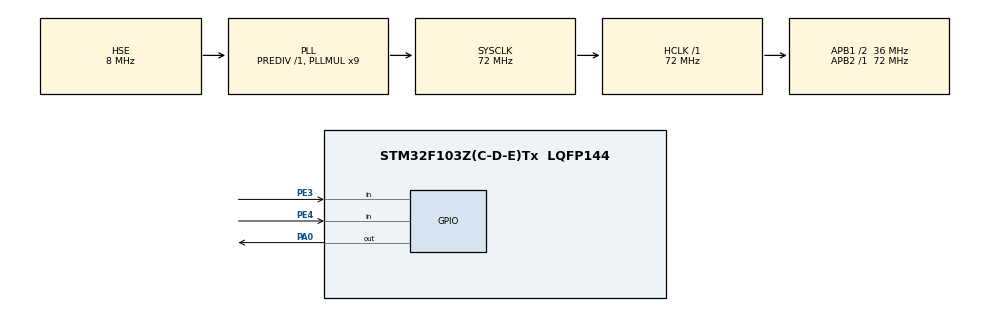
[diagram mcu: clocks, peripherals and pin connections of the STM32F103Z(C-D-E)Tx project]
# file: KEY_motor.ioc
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Mcu.Family=STM32F1
Mcu.Name=STM32F103Z(C-D-E)Tx
Mcu.Package=LQFP144
NVIC.PriorityGroup=NVIC_PRIORITYGROUP_4
OSC_IN.Mode=HSE-External-Oscillator
OSC_IN.Signal=RCC_OSC_IN
OSC_OUT.Mode=HSE-External-Oscillator
OSC_OUT.Signal=RCC_OSC_OUT
PA0-WKUP.GPIO_PuPd=GPIO_PULLUP
PA0-WKUP.GPIO_Speed=GPIO_SPEED_FREQ_HIGH
PA0-WKUP.PinState=GPIO_PIN_SET
PA0-WKUP.Signal=GPIO_Output
PA13.Mode=JTAG_5_pins
PA13.Signal=SYS_JTMS-SWDIO
PA14.Mode=JTAG_5_pins
PA14.Signal=SYS_JTCK-SWCLK
PA15.Mode=JTAG_5_pins
PA15.Signal=SYS_JTDI
PB3.Mode=JTAG_5_pins
PB3.Signal=SYS_JTDO-TRACESWO
PB4.Mode=JTAG_5_pins
PB4.Signal=SYS_NJTRST
PC14-OSC32_IN.Mode=LSE-External-Oscillator
PC14-OSC32_IN.Signal=RCC_OSC32_IN
PC15-OSC32_OUT.Mode=LSE-External-Oscillator
PC15-OSC32_OUT.Signal=RCC_OSC32_OUT
PE3.GPIO_PuPd=GPIO_PULLUP
PE3.Signal=GPIO_Input
PE4.GPIO_PuPd=GPIO_PULLUP
PE4.Signal=GPIO_Input
ProjectManager.HeapSize=0x200
ProjectManager.StackSize=0x400
ProjectManager.TargetToolchain=MDK-ARM V5.32
RCC.AHBFreq_Value=72000000
RCC.APB1CLKDivider=RCC_HCLK_DIV2
RCC.APB1Freq_Value=36000000
RCC.APB1TimFreq_Value=72000000
RCC.APB2Freq_Value=72000000
RCC.APB2TimFreq_Value=72000000
RCC.HCLKFreq_Value=72000000
RCC.PLLMUL=RCC_PLL_MUL9
RCC.PLLSourceVirtual=RCC_PLLSOURCE_HSE
RCC.SYSCLKFreq_VALUE=72000000
RCC.SYSCLKSource=RCC_SYSCLKSOURCE_PLLCLK
RCC.USBFreq_Value=72000000
board=custom

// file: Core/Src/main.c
/* USER CODE BEGIN Header */
/**
 ******************************************************************************
 * @file           : main.c
 * @brief          : Main program body
 ******************************************************************************
 * @attention
 *
 * Copyright (c) 2024 STMicroelectronics.
 * All rights reserved.
 *
 * This software is licensed under terms that can be found in the LICENSE file
 * in the root directory of this software component.
 * If no LICENSE file comes with this software, it is provided AS-IS.
 *
 ******************************************************************************
 */
/* USER CODE END Header */
#include "main.h"

void SystemClock_Config(void);
static void MX_GPIO_Init(void);

/* USER CODE BEGIN 0 */
void delay_us(uint32_t us)
{
  uint32_t count = us * (SystemCoreClock / 1000000) / 9;
  while (count--);
}

/* USER CODE END 0 */

int main(void)
{

  /* MCU Configuration--------------------------------------------------------*/

  /* Reset of all peripherals, Initializes the Flash interface and the Systick. */
  HAL_Init();

  /* Configure the system clock */
  SystemClock_Config();

  /* Initialize all configured peripherals */
  MX_GPIO_Init();
  /* USER CODE BEGIN 2 */
  uint16_t i = 0;
  /* USER CODE END 2 */

  /* Infinite loop */
  while (1)
  {

    /* USER CODE BEGIN 3 */

      for (i = 1500; i >= 500; i -= 10)
      {
        PA0(1);
        delay_us(i);
        PA0(0);
        delay_us(20000-i);
      }
      //for (i = 500; i <= 1500; i += 10)
      //{
      //  PA0(1);
      //  delay_us(i);
      //  PA0(0);
      //  delay_us(20000-i);
      //}
  }
  /* USER CODE END 3 */
}

void SystemClock_Config(void)
{
  RCC_OscInitTypeDef RCC_OscInitStruct = {0};
  RCC_ClkInitTypeDef RCC_ClkInitStruct = {0};

  /** Initializes the RCC Oscillators according to the specified parameters
   * in the RCC_OscInitTypeDef structure.
   */
  RCC_OscInitStruct.OscillatorType = RCC_OSCILLATORTYPE_HSE;
  RCC_OscInitStruct.HSEState = RCC_HSE_ON;
  RCC_OscInitStruct.HSEPredivValue = RCC_HSE_PREDIV_DIV1;
  RCC_OscInitStruct.HSIState = RCC_HSI_ON;
  RCC_OscInitStruct.PLL.PLLState = RCC_PLL_ON;
  RCC_OscInitStruct.PLL.PLLSource = RCC_PLLSOURCE_HSE;
  RCC_OscInitStruct.PLL.PLLMUL = RCC_PLL_MUL9;
  if (HAL_RCC_OscConfig(&RCC_OscInitStruct) != HAL_OK)
  {
    Error_Handler();
  }

  /** Initializes the CPU, AHB and APB buses clocks
   */
  RCC_ClkInitStruct.ClockType = RCC_CLOCKTYPE_HCLK | RCC_CLOCKTYPE_SYSCLK | RCC_CLOCKTYPE_PCLK1 | RCC_CLOCKTYPE_PCLK2;
  RCC_ClkInitStruct.SYSCLKSource = RCC_SYSCLKSOURCE_PLLCLK;
  RCC_ClkInitStruct.AHBCLKDivider = RCC_SYSCLK_DIV1;
  RCC_ClkInitStruct.APB1CLKDivider = RCC_HCLK_DIV2;
  RCC_ClkInitStruct.APB2CLKDivider = RCC_HCLK_DIV1;

  if (HAL_RCC_ClockConfig(&RCC_ClkInitStruct, FLASH_LATENCY_2) != HAL_OK)
  {
    Error_Handler();
  }
}

static void MX_GPIO_Init(void)
{
  GPIO_InitTypeDef GPIO_InitStruct = {0};

  /* GPIO Ports Clock Enable */
  __HAL_RCC_GPIOE_CLK_ENABLE();
  __HAL_RCC_GPIOC_CLK_ENABLE();
  __HAL_RCC_GPIOA_CLK_ENABLE();
  __HAL_RCC_GPIOB_CLK_ENABLE();

  /*Configure GPIO pin Output Level */
  HAL_GPIO_WritePin(GPIOA, GPIO_PIN_0, GPIO_PIN_SET);

  /*Configure GPIO pins : PE3 PE4 */
  GPIO_InitStruct.Pin = GPIO_PIN_3 | GPIO_PIN_4;
  GPIO_InitStruct.Mode = GPIO_MODE_INPUT;
  GPIO_InitStruct.Pull = GPIO_PULLUP;
  HAL_GPIO_Init(GPIOE, &GPIO_InitStruct);

  /*Configure GPIO pin : PA0 */
  GPIO_InitStruct.Pin = GPIO_PIN_0;
  GPIO_InitStruct.Mode = GPIO_MODE_OUTPUT_PP;
  GPIO_InitStruct.Pull = GPIO_PULLUP;
  GPIO_InitStruct.Speed = GPIO_SPEED_FREQ_HIGH;
  HAL_GPIO_Init(GPIOA, &GPIO_InitStruct);

  /* USER CODE BEGIN MX_GPIO_Init_2 */
  PA0(0);
  /* USER CODE END MX_GPIO_Init_2 */
}

/* USER CODE BEGIN 4 */
uint8_t KEY_scan(void)
{
  if (KEY0 == 0)
    return 0U;
  if (KEY1 == 0)
    return 1U;

  return 2U;
}
/* USER CODE END 4 */

void Error_Handler(void)
{
  __disable_irq();
  while (1)
  {
  }
}
